# NUC123BN_v1 register map
File version: 1.0
Registers are 32-bit, read-write, reset 0x0 unless marked. A register's access mark holds for its fields unless they carry their own. Offsets are from the block's base; [hi:lo] are bit positions; {n}, {i} and the like mark numbered series.

## I2S — I2S Register Map
Base 0x401A0000
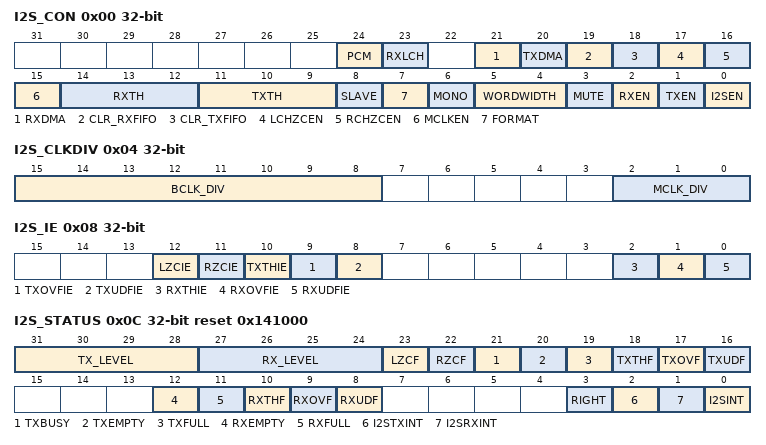
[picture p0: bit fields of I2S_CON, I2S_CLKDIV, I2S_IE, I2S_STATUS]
0x00 I2S_CON — I2S Control Register
  [24] PCM — PCM Interface Enable
    0=I2S Interface; 1=PCM interface
  [23] RXLCH — Receive Left Channel Enable
    0=Receives right channel data when monaural format is selected; 1=Receives left channel data when monaural format is selected
  [21] RXDMA — Enable Receive DMA. When RX DMA is enabled, I2S requests DMA to transfer data from receive FIFO to SRAM if FIFO is not empty.
    0=RX DMA Disabled; 1=RX DMA Enabled
  [20] TXDMA — Enable Transmit DMA. When TX DMA is enables, I2S request DMA to transfer data from SRAM to transmit FIFO if FIFO is not full.
    0=TX DMA Disabled; 1=TX DMA Enabled
  [19] CLR_RXFIFO — Clear Receive FIFO. Write 1 to clear receive FIFO, internal pointer is reset to FIFO start point, and RXFIFO_LEVEL[3:0] returns to zero and receive FIFO becomes empty. This bit is cleared by hardware automatically, reading it returns zero.
  [18] CLR_TXFIFO — Clear Transmit FIFO. Write 1 to clear transmit FIFO, internal pointer is reset to FIFO start point, and TXFIFO_LEVEL[3:0] returns to zero and transmit FIFO becomes empty but data in transmit FIFO is not changed. This bit is cleared by hardware automatically, reading it returns zero.
  [17] LCHZCEN — Left Channel Zero Cross Detect Enable. If this bit is set to 1, when left channel data sign bit change or next shift data bits are all zero then LZCF flag in I2S_STATUS register is set to 1.
    0=Left channel zero-cross detect Disabled; 1=Left channel zero-cross detect Enabled
  [16] RCHZCEN — Right Channel Zero-cross Detect Enable. If this bit is set to 1, when left channel data sign bit change or next shift data bits are all zero then LZCF flag in I2S_STATUS register is set to 1.
    0=Right channel zero-cross detect Disabled; 1=Right channel zero-cross detect Enabled
  [15] MCLKEN — Master clock enable. For NuMicro( NUC123 series, if the external crystal clock is frequency 2*N*256fs, software can program MCLK_DIV[2:0] in I2S_CLKDIV register to get 256fs clock to audio codec chip.
    0=Master clock Disabled; 1=Master clock Enabled
  [14:12] RXTH — Receive FIFO threshold level. When received data word(s) in buffer is equal to or higher than threshold level, the RXTHF flag is set.
    {v}={v+1} word data in receive FIFO (v=0..7)
  [11:9] TXTH — Transmit FIFO threshold level. If remain data word (32 bits) in transmit FIFO is the same or less than threshold level, the TXTHF flag is set.
    0=0 word data in transmit FIFO; 1=1 word data in transmit FIFO; {v}={v} words data in transmit FIFO (v=2..7)
  [8] SLAVE — Slave mode. I2S can be operated as Master or Slave mode. For Master mode, I2S_BCLK and I2S_LRCLK pins are output mode and send bit clock from NuMicro( NUC123 series to Audio CODEC chip. In Slave mode, I2S_BCLK and I2S_LRCLK pins are input mode and I2S_BCLK and I2S_LRCLK signals are received from outer Audio CODEC chip.
    0=Master mode; 1=Slave mode
  [7] FORMAT — Data format Selection
    0=I2S data format. PCM mode A; 1=MSB justified data format. PCM mode B
  [6] MONO — Monaural Data
    0=Data is stereo format; 1=Data is monaural format
  [5:4] WORDWIDTH
    0=Data is 8-bit; 1=Data is 16-bit; 2=Data is 24-bit; 3=Data is 32-bit
  [3] MUTE — Transmit Mute Enable
    0=Transmit data is shifted from buffer; 1=Transmit channel zero
  [2] RXEN — Receive enable
    0=Data receiving Disabled; 1=Data receiving Enabled
  [1] TXEN — Transmit enable
    0=Data transmission Disabled; 1=Data transmission Enabled
  [0] I2SEN — I2S Controller Enable
    0=Disabled; 1=Enabled
0x04 I2S_CLKDIV — I2S Clock Divider Register
  [15:8] BCLK_DIV — Bit Clock Divider. If I2S operates in Master mode, bit clock is provided by NuMicro( NUC123 series. Software can program these bits to generate sampling rate clock frequency.
  [2:0] MCLK_DIV — Master Clock Divider. If chip external crystal frequency is (2xMCLK_DIV)*256fs then software can program these bits to generate 256fs clock frequency to audio codec chip. If MCLK_DIV is set to 0, MCLK is the same as external clock input.
0x08 I2S_IE — I2S Interrupt Enable Register
  [all] fields
    0=Interrupt Disabled; 1=Interrupt Enabled
  [12] LZCIE — Left Channel Zero-cross Interrupt Enable. Interrupt occurs if this bit is set to 1 and left channel zero-cross.
  [11] RZCIE — Right Channel Zero-cross Interrupt Enable
  [10] TXTHIE — Transmitted FIFO Threshold Level Interrupt Enable. Interrupt occurs if this bit is set to 1 and data words in transmit FIFO are less than TXTH[2:0].
  [9] TXOVFIE — Transmitted FIFO Overflow Interrupt Enable. Interrupt occurs if this bit is set to 1 and transmitted FIFO overflow flag is set to 1.
  [8] TXUDFIE — Transmitted FIFO Underflow Interrupt Enable. Interrupt occurs if this bit is set to 1 and transmitted FIFO underflow flag is set to 1.
  [2] RXTHIE — Received FIFO Threshold Level Interrupt Enable. When data word in receive FIFO is equal to or higher then RXTH[2:0] and the RXTHF bit is set to 1. If RXTHIE bit is enabled, interrupt occurs.
  [1] RXOVFIE — Receive FIFO Overflow Interrupt Enable
  [0] RXUDFIE — Receive FIFO Underflow Interrupt Enable. If software reads the received FIFO when it is empty, RXUDF flag in I2SSTATUS register is set to 1.
0x0C I2S_STATUS reset 0x141000
  [31:28] TX_LEVEL — Transmit FIFO Level. These bits indicate word number in transmit FIFO.
    0=No data; 1=1 word in transmit FIFO; 8=8 words in transmit FIFO
  [27:24] RX_LEVEL — Receive FIFO Level. These bits indicate word number in receive FIFO.
    0=No data; 1=1 word in receive FIFO; 8=8 words in receive FIFO
  [23] LZCF — Left Channel Zero-cross Flag. It indicates left channel next the sample data sign bit is changed or all data bits are zero. Software can write 1 to clear this bit to zero
    0=No zero-cross; 1=Left channel zero-cross is detected
  [22] RZCF — Right Channel Zero-cross Flag. It indicates right channel next sample data sign bit is changed or all data bits are zero. Software can write 1 to clear this bit to zero.
    0=No zero-cross; 1=Right channel zero-cross is detected
  [21] TXBUSY — Transmit Busy. This bit is cleared to 0 when all data in transmit FIFO and shift buffer is shifted out, and set to 1 when the 1st data is load to shift buffer. This bit is read only.
    0=Transmit shift buffer is empty; 1=Transmit shift buffer is busy
  [20] TXEMPTY — Transmit FIFO Empty. This bit reflect data word number in transmit FIFO is zero. This bit is read only.
    0=Not empty; 1=Empty
  [19] TXFULL — Transmit FIFO Full. This bit reflect data word number in transmit FIFO is 8. This bit is read only
    0=Not full; 1=Full
  [18] TXTHF — Transmit FIFO Threshold Flag. When data word(s) in transmit FIFO is equal to or lower than threshold value set in TXTH[2:0] the TXTHF bit becomes to 1. It keeps at 1 till TXFIFO_LEVEL[3:0] is higher than TXTH[1:0] after software write TXFIFO register. This bit is read only.
    0=Data word(s) in FIFO is higher than threshold level; 1=Data word(s) in FIFO is equal or lower than threshold level
  [17] TXOVF — Transmit FIFO Overflow Flag. Write data to transmit FIFO when it is full and this bit set to 1. Software can write 1 to clear this bit to zero.
    0=No overflow; 1=Overflow
  [16] TXUDF — Transmit FIFO underflow flag. When transmit FIFO is empty and shift logic hardware read data from data FIFO causes this set to 1. Software can write 1 to clear this bit to zero
    0=No underflow; 1=Underflow
  [12] RXEMPTY — Receive FIFO Empty. This bit reflects data words number in receive FIFO is zero. This bit is read only.
    0=Not empty; 1=Empty
  [11] RXFULL — Receive FIFO Full. This bit reflect data words number in receive FIFO is 8. This bit is read only.
    0=Not full; 1=Full
  [10] RXTHF — Receive FIFO Threshold Flag. When data word(s) in receive FIFO is equal or higher than threshold value set in RXTH[2:0] the RXTHF bit becomes to 1. It keeps at 1 till RXFIFO_LEVEL[3:0] less than RXTH[1:0] after software read RXFIFO register. This bit is read only.
    0=Data word(s) in FIFO is lower than threshold level; 1=Data word(s) in FIFO is equal or higher than threshold level
  [9] RXOVF — Receive FIFO Overflow Flag. When receive FIFO is full and receive hardware attempt write to data into receive FIFO then this bit is set to 1, data in 1st buffer is overwrote. Software can write 1 to clear this bit to zero.
    0=No overflow occurred; 1=Overflow occurred
  [8] RXUDF — Receive FIFO Underflow Flag. Read receive FIFO when it is empty, this bit set to 1 indicate underflow occur. Software can write 1 to clear this bit to zero.
    0=No underflow occurred; 1=Underflow occurred
  [3] RIGHT — Right Channel. This bit indicates the current transmit data is belong to right channel. This bit is read only.
    0=Left channel; 1=Right channel
  [2] I2STXINT — I2S Transmit Interrupt. This bit is read only.
    0=No transmit interrupt; 1=Transmit interrupt
  [1] I2SRXINT — I2S Receive Interrupt. This bit is read only.
    0=No receive interrupt; 1=Receive interrupt
  [0] I2SINT — I2S Interrupt Flag. It is wire-OR of I2STXINT and I2SRXINT bits. This bit is read only.
    0=No I2S interrupt; 1=I2S interrupt
0x10 I2S_TXFIFO — I2S Transmit FIFO Register
  [31:0] TXFIFO — Transmit FIFO register. I2S contains 8 words (8x32 bit) data buffer for data transmission. Write data to this register to prepare data for transmit. The remaining word number is indicated by TX_LEVEL[3:0] in I2S_STATUS.
0x14 I2S_RXFIFO — I2S Receive FIFO Register
  [31:0] RXFIFO — Receive FIFO register. I2S contains 8 words (8x32 bit) data buffer for data receive. Read this register to get data in FIFO. The remaining data word number is indicated by RX_LEVEL[3:0] in I2S_STATUS register.
